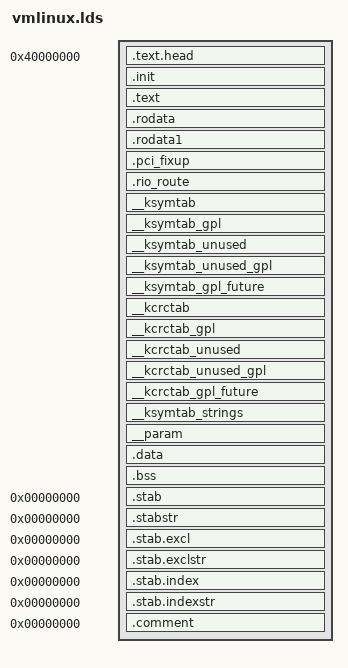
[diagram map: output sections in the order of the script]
/*
 * Automatically generated C config: don't edit
 * Linux kernel version: 2.6.23
 * Fri Dec 25 02:12:07 2009
 */
/* ld script to make lm32 Linux kernel
 * taken from the arm version by Martin Mares
 */
/*
 * DO NOT MODIFY.
 *
 * This file was generated by Kbuild
 *
 */
/* Align . to a 8 byte boundary equals to maximum function alignment. */
/* .data section */
/* RODATA provided for backward compatibility.
 * All archs are supposed to use RO_DATA() */
/* .text section. Map to function alignment to avoid address changes
 * during second ld run in second ld pass when generating System.map */
/* sched.text is aling to function alignment to secure we have same
 * address even at second ld pass when generating System.map */
/* spinlock.text is aling to function alignment to secure we have same
 * address even at second ld pass when generating System.map */
  /* DWARF debug sections.
		Symbols in the DWARF debugging sections are relative to
		the beginning of the section so we begin them at 0.  */
  /* Stabs debugging sections.  */
/*
 * (C) Copyright 2007
 *     Theobroma Systems <www.theobroma-systems.com>
 *
 * See file CREDITS for list of people who contributed to this
 * project.
 *
 * This program is free software; you can redistribute it and/or
 * modify it under the terms of the GNU General Public License as
 * published by the Free Software Foundation; either version 2 of
 * the License, or (at your option) any later version.
 *
 * This program is distributed in the hope that it will be useful,
 * but WITHOUT ANY WARRANTY; without even the implied warranty of
 * MERCHANTABILITY or FITNESS FOR A PARTICULAR PURPOSE.  See the
 * GNU General Public License for more details.
 *
 * You should have received a copy of the GNU General Public License
 * along with this program; if not, write to the Free Software
 * Foundation, Inc., 59 Temple Place, Suite 330, Boston,
 * MA 02111-1307 USA
 */
/*
 * (C) Copyright 2007
 *     Theobroma Systems <www.theobroma-systems.com>
 *
 * See file CREDITS for list of people who contributed to this
 * project.
 *
 * This program is free software; you can redistribute it and/or
 * modify it under the terms of the GNU General Public License as
 * published by the Free Software Foundation; either version 2 of
 * the License, or (at your option) any later version.
 *
 * This program is distributed in the hope that it will be useful,
 * but WITHOUT ANY WARRANTY; without even the implied warranty of
 * MERCHANTABILITY or FITNESS FOR A PARTICULAR PURPOSE.  See the
 * GNU General Public License for more details.
 *
 * You should have received a copy of the GNU General Public License
 * along with this program; if not, write to the Free Software
 * Foundation, Inc., 59 Temple Place, Suite 330, Boston,
 * MA 02111-1307 USA
 */
/*
 * Based on:
 * include/asm-v850/page.h -- VM ops
 *
 *  Copyright (C) 2001,02,03,05  NEC Electronics Corporation
 *  Copyright (C) 2001,02,03,05  Miles Bader <miles@gnu.org>
 *
 * This file is subject to the terms and conditions of the GNU General
 * Public License.  See the file COPYING in the main directory of this
 * archive for more details.
 *
 * Written by Miles Bader <miles@gnu.org>
 */
/*
 * (C) Copyright 2007
 *     Theobroma Systems <www.theobroma-systems.com>
 *
 * See file CREDITS for list of people who contributed to this
 * project.
 *
 * This program is free software; you can redistribute it and/or
 * modify it under the terms of the GNU General Public License as
 * published by the Free Software Foundation; either version 2 of
 * the License, or (at your option) any later version.
 *
 * This program is distributed in the hope that it will be useful,
 * but WITHOUT ANY WARRANTY; without even the implied warranty of
 * MERCHANTABILITY or FITNESS FOR A PARTICULAR PURPOSE.  See the
 * GNU General Public License for more details.
 *
 * You should have received a copy of the GNU General Public License
 * along with this program; if not, write to the Free Software
 * Foundation, Inc., 59 Temple Place, Suite 330, Boston,
 * MA 02111-1307 USA
 */
/*
 * Based on:
 * include/asm-m68knommu/io.h
 *
 * lm32 does not currently support ISA/PCI
 */
/* PAGE_SHIFT determines the page size */
/* TODO: determine good page size, 12 means 2^12 bytes page size */
/*
 * (C) Copyright 2007
 *     Theobroma Systems <www.theobroma-systems.com>
 *
 * See file CREDITS for list of people who contributed to this
 * project.
 *
 * This program is free software; you can redistribute it and/or
 * modify it under the terms of the GNU General Public License as
 * published by the Free Software Foundation; either version 2 of
 * the License, or (at your option) any later version.
 *
 * This program is distributed in the hope that it will be useful,
 * but WITHOUT ANY WARRANTY; without even the implied warranty of
 * MERCHANTABILITY or FITNESS FOR A PARTICULAR PURPOSE.  See the
 * GNU General Public License for more details.
 *
 * You should have received a copy of the GNU General Public License
 * along with this program; if not, write to the Free Software
 * Foundation, Inc., 59 Temple Place, Suite 330, Boston,
 * MA 02111-1307 USA
 */
/*
 * thread information flag bit numbers
 */
/* as above, but as bit values */
OUTPUT_ARCH(lm32)
ENTRY(stext)
jiffies = jiffies_64 + 4;
SECTIONS
{
 . = 0x40000000;
 _stext = .; /* save begin of text section */
 .text.head : {
  _sinittext = .;
  *(.text.head)
 }
 .init : { /* Init code and data		*/
   *(.init.text)
  _einittext = .;
  __proc_info_begin = .;
   *(.proc.info.init)
  __proc_info_end = .;
  __arch_info_begin = .;
   *(.arch.info.init)
  __arch_info_end = .;
  __tagtable_begin = .;
   *(.taglist.init)
  __tagtable_end = .;
  . = ALIGN(16);
  __setup_start = .;
   *(.init.setup)
  __setup_end = .;
  __early_begin = .;
   *(.early_param.init)
  __early_end = .;
  __initcall_start = .;
   *(.initcall0.init) *(.initcall0s.init) *(.initcall1.init) *(.initcall1s.init) *(.initcall2.init) *(.initcall2s.init) *(.initcall3.init) *(.initcall3s.init) *(.initcall4.init) *(.initcall4s.init) *(.initcall5.init) *(.initcall5s.init) *(.initcallrootfs.init) *(.initcall6.init) *(.initcall6s.init) *(.initcall7.init) *(.initcall7s.init)
  __initcall_end = .;
  __con_initcall_start = .;
   *(.con_initcall.init)
  __con_initcall_end = .;
  __security_initcall_start = .;
   *(.security_initcall.init)
  __security_initcall_end = .;
  . = ALIGN(32);
  __initramfs_start = .;
   usr/built-in.o(.init.ramfs)
  __initramfs_end = .;
  . = ALIGN(4096);
  __per_cpu_start = .;
   *(.data.percpu)
  __per_cpu_end = .;
  __init_begin = _stext;
  *(.init.data)
  . = ALIGN(4096);
  __init_end = .;
 }
 /DISCARD/ : { /* Exit code and data		*/
  *(.exit.text)
  *(.exit.data)
  *(.exitcall.exit)
  *(.fixup)
  *(__ex_table)
 }
 .text : { /* Real text segment		*/
  _text = .; /* Text and read-only data	*/
   . = ALIGN(256);
   __exception_text_start = .;
   *(.exception.text)
   __exception_text_end = .;
   . = ALIGN(8); *(.text) *(.text.init.refok)
   . = ALIGN(8); __sched_text_start = .; *(.sched.text) __sched_text_end = .;
   . = ALIGN(8); __lock_text_start = .; *(.spinlock.text) __lock_text_end = .;
   *(.gnu.warning)
   *(.glue_7)
   *(.glue_7t)
  *(.got) /* Global offset table		*/
 }
 . = ALIGN((4096)); .rodata : AT(ADDR(.rodata) - 0) { __start_rodata = .; *(.rodata) *(.rodata.*) *(__vermagic) } .rodata1 : AT(ADDR(.rodata1) - 0) { *(.rodata1) } .pci_fixup : AT(ADDR(.pci_fixup) - 0) { __start_pci_fixups_early = .; *(.pci_fixup_early) __end_pci_fixups_early = .; __start_pci_fixups_header = .; *(.pci_fixup_header) __end_pci_fixups_header = .; __start_pci_fixups_final = .; *(.pci_fixup_final) __end_pci_fixups_final = .; __start_pci_fixups_enable = .; *(.pci_fixup_enable) __end_pci_fixups_enable = .; __start_pci_fixups_resume = .; *(.pci_fixup_resume) __end_pci_fixups_resume = .; } .rio_route : AT(ADDR(.rio_route) - 0) { __start_rio_route_ops = .; *(.rio_route_ops) __end_rio_route_ops = .; } __ksymtab : AT(ADDR(__ksymtab) - 0) { __start___ksymtab = .; *(__ksymtab) __stop___ksymtab = .; } __ksymtab_gpl : AT(ADDR(__ksymtab_gpl) - 0) { __start___ksymtab_gpl = .; *(__ksymtab_gpl) __stop___ksymtab_gpl = .; } __ksymtab_unused : AT(ADDR(__ksymtab_unused) - 0) { __start___ksymtab_unused = .; *(__ksymtab_unused) __stop___ksymtab_unused = .; } __ksymtab_unused_gpl : AT(ADDR(__ksymtab_unused_gpl) - 0) { __start___ksymtab_unused_gpl = .; *(__ksymtab_unused_gpl) __stop___ksymtab_unused_gpl = .; } __ksymtab_gpl_future : AT(ADDR(__ksymtab_gpl_future) - 0) { __start___ksymtab_gpl_future = .; *(__ksymtab_gpl_future) __stop___ksymtab_gpl_future = .; } __kcrctab : AT(ADDR(__kcrctab) - 0) { __start___kcrctab = .; *(__kcrctab) __stop___kcrctab = .; } __kcrctab_gpl : AT(ADDR(__kcrctab_gpl) - 0) { __start___kcrctab_gpl = .; *(__kcrctab_gpl) __stop___kcrctab_gpl = .; } __kcrctab_unused : AT(ADDR(__kcrctab_unused) - 0) { __start___kcrctab_unused = .; *(__kcrctab_unused) __stop___kcrctab_unused = .; } __kcrctab_unused_gpl : AT(ADDR(__kcrctab_unused_gpl) - 0) { __start___kcrctab_unused_gpl = .; *(__kcrctab_unused_gpl) __stop___kcrctab_unused_gpl = .; } __kcrctab_gpl_future : AT(ADDR(__kcrctab_gpl_future) - 0) { __start___kcrctab_gpl_future = .; *(__kcrctab_gpl_future) __stop___kcrctab_gpl_future = .; } __ksymtab_strings : AT(ADDR(__ksymtab_strings) - 0) { *(__ksymtab_strings) } __param : AT(ADDR(__param) - 0) { __start___param = .; *(__param) __stop___param = .; __end_rodata = .; } . = ALIGN((4096));
 _etext = .; /* save end of text section */
 . = ALIGN(16384);
 __data_loc = .;
 .data : AT(__data_loc) {
  _sdata = .; /* save start of data section */
  /*
		 * first, the init task union, aligned
		 * to an 8192 byte boundary.
		 */
  *(.data.init_task)
  . = ALIGN(4096);
  __nosave_begin = .;
  *(.data.nosave)
  . = ALIGN(4096);
  __nosave_end = .;
  /*
		 * then the cacheline aligned data
		 */
  . = ALIGN(32);
  *(.data.cacheline_aligned)
  /*
		 * The exception fixup table (might need resorting at runtime)
		 */
  . = ALIGN(32);
  __start___ex_table = .;
  __stop___ex_table = .;
  /*
		 * and the usual data section
		 */
  *(.data) *(.data.init.refok)
  CONSTRUCTORS
  _edata = .; /* save end of data section */
 }
 _edata_loc = __data_loc + SIZEOF(.data);
 .bss : {
  __bss_start = .; /* BSS				*/
  *(.bss)
  *(COMMON)
  __bss_stop = .; /* save end of bss section */
 }
 _end = .;
     /* Stabs debugging sections.	*/
 .stab 0 : { *(.stab) }
 .stabstr 0 : { *(.stabstr) }
 .stab.excl 0 : { *(.stab.excl) }
 .stab.exclstr 0 : { *(.stab.exclstr) }
 .stab.index 0 : { *(.stab.index) }
 .stab.indexstr 0 : { *(.stab.indexstr) }
 .comment 0 : { *(.comment) }
}
